# L4PER_PRM register map
Vendor: Texas Instruments
Peripheral module from a debugger description file (folder omap4460).
Registers are 32-bit, access not given, reset 0x1 unless marked. A register's access mark holds for its fields unless they carry their own. Offsets are as the file gives them; lines under a group give offsets from that group; [hi:lo] are bit positions; {n}, {i} and the like mark numbered series; 'fields as' and 'values as' point back to an identical list; <NAME> marks a mode.

## L4PER_PRM
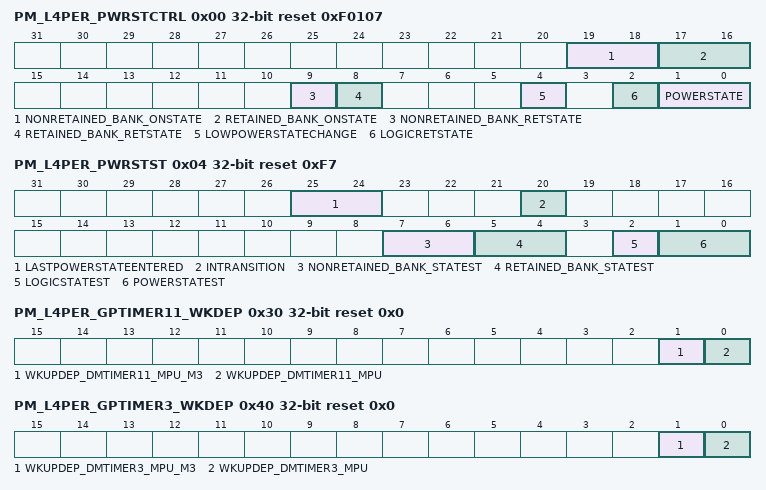
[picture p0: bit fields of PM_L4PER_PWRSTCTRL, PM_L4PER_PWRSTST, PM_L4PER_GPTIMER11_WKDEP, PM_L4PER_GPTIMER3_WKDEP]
0x00 PM_L4PER_PWRSTCTRL reset 0xF0107 — This register controls the L4PER power state to reach upon a domain sleep transition
  [19:18] NONRETAINED_BANK_ONSTATE — NONRETAINED_BANK state when domain is ON. (access R Rreturns1s)
    3=NONRETAINED_BANK_ONSTATE_3_r (Memory bank is on when the domain is ON.)
  [17:16] RETAINED_BANK_ONSTATE — RETAINED_BANK state when domain is ON. (access R Rreturns1s)
    3=RETAINED_BANK_ONSTATE_3_r (Memory bank is on when the domain is ON.)
  [9] NONRETAINED_BANK_RETSTATE ro — NONRETAINED_BANK state when domain is RETENTION.
    0=NONRETAINED_BANK_RETSTATE_0_r (Memory bank is off when the domain is in the RETENTION state.)
  [8] RETAINED_BANK_RETSTATE — RETAINED_BANK state when domain is RETENTION. (access R Rreturns1s)
    1=RETAINED_BANK_RETSTATE_1_r (Memory bank is retained when domain is in RETENTION state.)
  [4] LOWPOWERSTATECHANGE — Power state change request when domain has already performed a sleep transition. Allows going into deeper low power state without waking up the power domain. (access RW WSpecial)
    0=Do not request a low power state change; 1=Request a low power state change. This bit is automatically cleared when the power state is effectively changed or when power state is ON.
  [2] LOGICRETSTATE rw — Logic state when power domain is RETENTION
    0=Only retention registers are retained and remaing logic is off when the domain is in RETENTION state; 1=Whole logic is retained when domain is in RETENTION state
  [1:0] POWERSTATE rw — Power state control
    1=RETENTION state; 2=INACTIVE state; 3=ON State
0x04 PM_L4PER_PWRSTST reset 0xF7 — This register provides a status on the current L4PER power domain state. [warm reset insensitive]
  [25:24] LASTPOWERSTATEENTERED — Last low power state entered. Set to 0x3 upon write of the same only. This register is intended for debug purpose only. (access RW W1toSet)
    3=LASTPOWERSTATEENTERED_3_r (Power domain was previously ON-ACTIVE); 2=LASTPOWERSTATEENTERED_2_r (Power domain was previously ON-INACTIVE); 1=LASTPOWERSTATEENTERED_1_r (Power domain was previously in RETENTION); 0=LASTPOWERSTATEENTERED_0_r (Power domain was previously OFF)
  [20] INTRANSITION ro — Domain transition status
    0=INTRANSITION_0_r (No ongoing transition on power domain); 1=INTRANSITION_1_r (Power domain transition is in progress.)
  [7:6] NONRETAINED_BANK_STATEST ro — NONRETAINED_BANK state status
    0=NONRETAINED_BANK_STATEST_0_r (Memory is OFF); 1=NONRETAINED_BANK_STATEST_1_r (Reserved); 2=NONRETAINED_BANK_STATEST_2_r (Reserved); 3=NONRETAINED_BANK_STATEST_3_r (Memory is ON)
  [5:4] RETAINED_BANK_STATEST ro — RETAINED_BANK state status
    0=RETAINED_BANK_STATEST_0_r (Memory is OFF); 1=RETAINED_BANK_STATEST_1_r (Memory is RETENTION); 2=RETAINED_BANK_STATEST_2_r (Reserved); 3=RETAINED_BANK_STATEST_3_r (Memory is ON)
  [2] LOGICSTATEST ro — Logic state status
    0=LOGICSTATEST_0_r (Logic in domain is OFF); 1=LOGICSTATEST_1_r (Logic in domain is ON)
  [1:0] POWERSTATEST ro — Current power state status
    0=POWERSTATEST_0_r (Reserved); 1=POWERSTATEST_1_r (Power domain is in RETENTION); 2=POWERSTATEST_2_r (Power domain is ON-INACTIVE); 3=POWERSTATEST_3_r (Power domain is ON-ACTIVE)
0x28 PM_L4PER_GPTIMER10_WKDEP — This register controls wakeup dependency based on DMTIMER10 service requests.
  [0] WKUPDEP_DMTIMER10_MPU — Wakeup dependency from DMTIMER10 module (softwareakeup signal) towards MPU + L3_1 + L3_2 domains (access R Rreturns1s)
    1=WKUPDEP_DMTIMER10_MPU_1_r (Dependency is enabled)
0x2C RM_L4PER_GPTIMER10_CONTEXT — This register contains dedicated DMTIMER10 context statuses. [warm reset insensitive]
  [0] LOSTCONTEXT_DFF — Specify if DFF-based context has been lost due to a previous power transition or other reset source. (set upon assertion of L4_PER_RST signal) (access RW W1toClr)
    0=Context has been maintained; 1=Context has been lost
0x30 PM_L4PER_GPTIMER11_WKDEP access per field reset 0x0 — This register controls wakeup dependency based on DMTIMER11 service requests.
  [1] WKUPDEP_DMTIMER11_MPU_M3 rw — Wakeup dependency from DMTIMER11 module (softwareakeup signal) towards MPU_A3 + L3_2 domains
    0=Dependency is disabled; 1=Dependency is enabled
  [0] WKUPDEP_DMTIMER11_MPU rw — Wakeup dependency from DMTIMER11 module (softwareakeup signal) towards MPU + L3_1 + L3_2 domains
    0=Dependency is disabled; 1=Dependency is enabled
0x34 RM_L4PER_GPTIMER11_CONTEXT — This register contains dedicated DMTIMER11 context statuses. [warm reset insensitive]
  fields as RM_L4PER_GPTIMER10_CONTEXT
0x38 PM_L4PER_GPTIMER2_WKDEP — This register controls wakeup dependency based on DMTIMER2 service requests.
  [0] WKUPDEP_DMTIMER2_MPU — Wakeup dependency from DMTIMER2 module (softwareakeup signal) towards MPU + L3_1 + L3_2 domains (access R Rreturns1s)
    1=WKUPDEP_DMTIMER2_MPU_1_r (Dependency is enabled)
{0x2C+8i} RM_L4PER_GPTIMER{i}_CONTEXT (i=2..4) — This register contains dedicated DMTIMER{i} context statuses. [warm reset insensitive]
  fields as RM_L4PER_GPTIMER10_CONTEXT
0x40 PM_L4PER_GPTIMER3_WKDEP access per field reset 0x0 — This register controls wakeup dependency based on DMTIMER3 service requests.
  [1] WKUPDEP_DMTIMER3_MPU_M3 rw — Wakeup dependency from DMTIMER3 module (softwareakeup signal) towards MPU_A3 + L3_2 domains
    0=Dependency is disabled; 1=Dependency is enabled
  [0] WKUPDEP_DMTIMER3_MPU rw — Wakeup dependency from DMTIMER3 module (softwareakeup signal) towards MPU + L3_1 + L3_2 domains
    0=Dependency is disabled; 1=Dependency is enabled
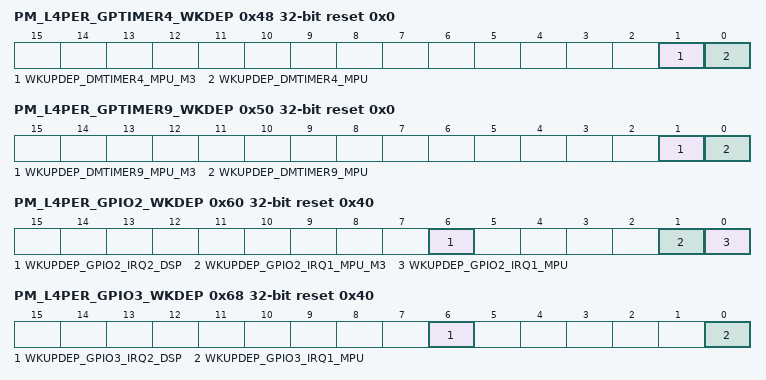
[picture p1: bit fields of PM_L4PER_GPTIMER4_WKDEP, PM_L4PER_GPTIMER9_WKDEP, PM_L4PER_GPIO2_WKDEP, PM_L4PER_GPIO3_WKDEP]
0x48 PM_L4PER_GPTIMER4_WKDEP access per field reset 0x0 — This register controls wakeup dependency based on DMTIMER4 service requests.
  [1] WKUPDEP_DMTIMER4_MPU_M3 rw — Wakeup dependency from DMTIMER4 module (softwareakeup signal) towards MPU_A3 + L3_2 domains
    0=Dependency is disabled; 1=Dependency is enabled
  [0] WKUPDEP_DMTIMER4_MPU rw — Wakeup dependency from DMTIMER4 module (softwareakeup signal) towards MPU + L3_1 + L3_2 domains
    0=Dependency is disabled; 1=Dependency is enabled
0x50 PM_L4PER_GPTIMER9_WKDEP access per field reset 0x0 — This register controls wakeup dependency based on DMTIMER9 service requests.
  [1] WKUPDEP_DMTIMER9_MPU_M3 rw — Wakeup dependency from DMTIMER9 module (softwareakeup signal) towards MPU_A3 + L3_2 domains
    0=Dependency is disabled; 1=Dependency is enabled
  [0] WKUPDEP_DMTIMER9_MPU rw — Wakeup dependency from DMTIMER9 module (softwareakeup signal) towards MPU + L3_1 + L3_2 domains
    0=Dependency is disabled; 1=Dependency is enabled
0x54 RM_L4PER_GPTIMER9_CONTEXT — This register contains dedicated DMTIMER9 context statuses. [warm reset insensitive]
  fields as RM_L4PER_GPTIMER10_CONTEXT
0x5C RM_L4PER_ELM_CONTEXT — This register contains dedicated ELM context statuses. [warm reset insensitive]
  fields as RM_L4PER_GPTIMER10_CONTEXT
0x60 PM_L4PER_GPIO2_WKDEP reset 0x40 — This register controls wakeup dependency based on GPIO2 service requests.
  [6] WKUPDEP_GPIO2_IRQ2_DSP — Wakeup dependency from GPIO2 module (POINTRsoftwareAKEUP2 signal) towards DSP + L3_1 + L3_2 domains (access R Rreturns1s)
    1=WKUPDEP_GPIO2_IRQ2_DSP_1_r (Dependency is enabled)
  [1] WKUPDEP_GPIO2_IRQ1_MPU_M3 rw — Wakeup dependency from GPIO2 module (POINTRsoftwareAKEUP1 signal) module towards MPU_A3 + L3_2 domains
    0=Dependency is disabled; 1=Dependency is enabled
  [0] WKUPDEP_GPIO2_IRQ1_MPU rw — Wakeup dependency from GPIO2 module (POINTRsoftwareAKEUP1 signal) towards MPU + L3_1 + L3_2 domains
    0=Dependency is disabled; 1=Dependency is enabled
{0x54+8i} RM_L4PER_GPIO{i}_CONTEXT reset 0x2 (i=2..6) — This register contains dedicated GPIO{i} context statuses. [warm reset insensitive]
  [1] LOSTCONTEXT_RFF — Specify if RFF-based context has been lost due to a previous power transition or other reset source. (set upon assertion of L4_PER_RET_RST signal) (access RW W1toClr)
    0=Context has been maintained; 1=Context has been lost
0x68 PM_L4PER_GPIO3_WKDEP reset 0x40 — This register controls wakeup dependency based on GPIO3 service requests.
  [6] WKUPDEP_GPIO3_IRQ2_DSP — Wakeup dependency from GPIO3 module (POINTRsoftwareAKEUP2 signal) towards DSP + L3_1 + L3_2 domains (access R Rreturns1s)
    1=WKUPDEP_GPIO3_IRQ2_DSP_1_r (Dependency is enabled)
  [0] WKUPDEP_GPIO3_IRQ1_MPU rw — Wakeup dependency from GPIO3 module (POINTRsoftwareAKEUP1 signal) towards MPU + L3_1 + L3_2 domains
    0=Dependency is disabled; 1=Dependency is enabled
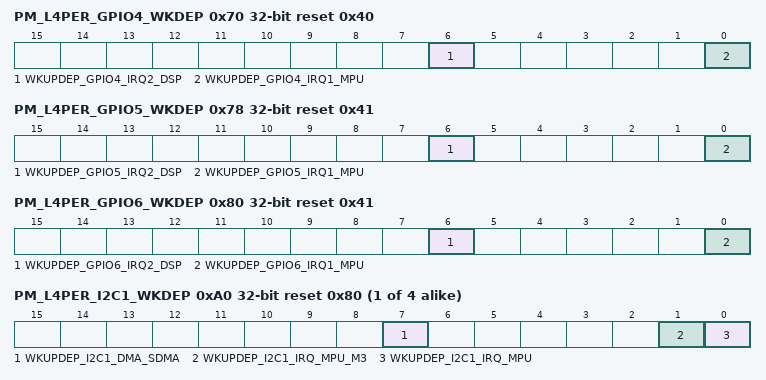
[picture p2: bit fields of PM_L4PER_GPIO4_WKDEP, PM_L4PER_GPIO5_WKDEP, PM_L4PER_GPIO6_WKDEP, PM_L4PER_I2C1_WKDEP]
0x70 PM_L4PER_GPIO4_WKDEP reset 0x40 — This register controls wakeup dependency based on GPIO4 service requests.
  [6] WKUPDEP_GPIO4_IRQ2_DSP — Wakeup dependency from GPIO4 module (POINTRsoftwareAKEUP2 signal) towards DSP + L3_1 + L3_2 domains (access R Rreturns1s)
    1=WKUPDEP_GPIO4_IRQ2_DSP_1_r (Dependency is enabled)
  [0] WKUPDEP_GPIO4_IRQ1_MPU rw — Wakeup dependency from GPIO4 module (POINTRsoftwareAKEUP1 signal) towards MPU + L3_1 + L3_2 domains
    0=Dependency is disabled; 1=Dependency is enabled
0x78 PM_L4PER_GPIO5_WKDEP reset 0x41 — This register controls wakeup dependency based on GPIO5 service requests.
  [6] WKUPDEP_GPIO5_IRQ2_DSP — Wakeup dependency from GPIO5 module (POINTRsoftwareAKEUP2 signal) towards DSP + L3_1 + L3_2 domains (access R Rreturns1s)
    1=WKUPDEP_GPIO5_IRQ2_DSP_1_r (Dependency is enabled)
  [0] WKUPDEP_GPIO5_IRQ1_MPU — Wakeup dependency from GPIO5 module (POINTRsoftwareAKEUP1 signal) towards MPU + L3_1 + L3_2 domains (access R Rreturns1s)
    1=WKUPDEP_GPIO5_IRQ1_MPU_1_r (Dependency is enabled)
0x80 PM_L4PER_GPIO6_WKDEP reset 0x41 — This register controls wakeup dependency based on GPIO6 service requests.
  [6] WKUPDEP_GPIO6_IRQ2_DSP — Wakeup dependency from GPIO6 module (POINTRsoftwareAKEUP2 signal) towards DSP + L3_1 + L3_2 domains (access R Rreturns1s)
    1=WKUPDEP_GPIO6_IRQ2_DSP_1_r (Dependency is enabled)
  [0] WKUPDEP_GPIO6_IRQ1_MPU — Wakeup dependency from GPIO6 module (POINTRsoftwareAKEUP1 signal) towards MPU + L3_1 + L3_2 domains (access R Rreturns1s)
    1=WKUPDEP_GPIO6_IRQ1_MPU_1_r (Dependency is enabled)
0x8C RM_L4PER_HDQ1W_CONTEXT — This register contains dedicated HDQ1W context statuses. [warm reset insensitive]
  fields as RM_L4PER_GPTIMER10_CONTEXT
{0x98+8i} PM_L4PER_I2C{i}_WKDEP reset 0x80 (i=1..4) — This register controls wakeup dependency based on I2C{i} service requests.
  [7] WKUPDEP_I2C{i}_DMA_SDMA — Wakeup dependency from I2C{i} module (softwareakeup_dma signal) towards SDMA + L3_2 domains (access R Rreturns1s)
    1=WKUPDEP_I2C{i}_DMA_SDMA_1_r (Dependency is enabled)
  [1] WKUPDEP_I2C{i}_IRQ_MPU_M3 rw — Wakeup dependency from I2C{i} module (softwareakeup_irq signal) towards MPU_A3 + L3_2 domains
    0=Dependency is disabled; 1=Dependency is enabled
  [0] WKUPDEP_I2C{i}_IRQ_MPU rw — Wakeup dependency from I2C{i} module (softwareakeup_irq signal) towards MPU + L3_1 + L3_2 domains
    0=Dependency is disabled; 1=Dependency is enabled
0xA4 RM_L4PER_I2C1_CONTEXT reset 0x2 — This register contains dedicated I2C1 context statuses. [warm reset insensitive]
  fields as RM_L4PER_GPIO2_CONTEXT
{0x9C+8i} RM_L4PER_I2C{i}_CONTEXT (i=2..4) — This register contains dedicated I2C{i} context statuses. [warm reset insensitive]
  fields as RM_L4PER_GPTIMER10_CONTEXT
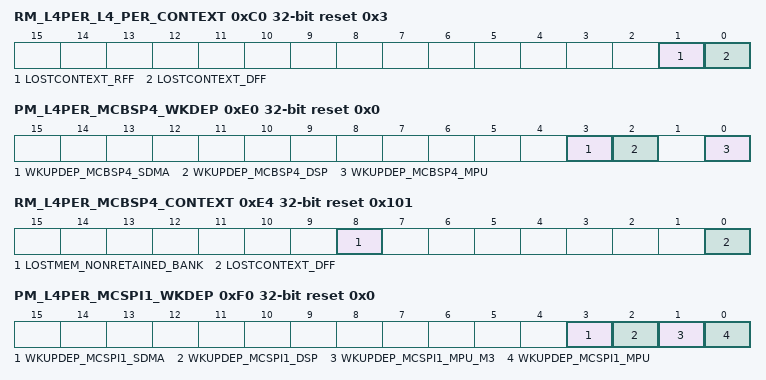
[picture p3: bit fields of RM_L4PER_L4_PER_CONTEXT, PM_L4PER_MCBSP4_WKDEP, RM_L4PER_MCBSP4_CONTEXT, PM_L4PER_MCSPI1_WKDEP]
0xC0 RM_L4PER_L4_PER_CONTEXT reset 0x3 — This register contains dedicated L4_PER context statuses. [warm reset insensitive]
  [1] LOSTCONTEXT_RFF — Specify if RFF-based context has been lost due to a previous power transition or other reset source. (set upon assertion of L4_PER_PWRON_RET_RST signal) (access RW W1toClr)
    0=Context has been maintained; 1=Context has been lost
  [0] LOSTCONTEXT_DFF — Specify if DFF-based context has been lost due to a previous power transition or other reset source. (set upon assertion of L4_PER_RST signal) (access RW W1toClr)
    0=Context has been maintained; 1=Context has been lost
0xE0 PM_L4PER_MCBSP4_WKDEP access per field reset 0x0 — This register controls wakeup dependency based on MCBSP4 service requests.
  [all] fields
    0=Dependency is disabled; 1=Dependency is enabled
  [3] WKUPDEP_MCBSP4_SDMA rw — Wakeup dependency from MCBSP4 module (softwareakeup signal) towards SDMA + L3_2 domains
  [2] WKUPDEP_MCBSP4_DSP rw — Wakeup dependency from MCBSP4 module (softwareakeup signal) towards DSP + L3_1 + L3_2 domain
  [0] WKUPDEP_MCBSP4_MPU rw — Wakeup dependency from MCBSP4 module (softwareakeup signal) towards MPU + L3_1 + L3_2 domain
0xE4 RM_L4PER_MCBSP4_CONTEXT reset 0x101 — This register contains dedicated MCBSP4 context statuses. [warm reset insensitive]
  [8] LOSTMEM_NONRETAINED_BANK — Specify if memory-based context in NONRETAINED_BANK memory bank has been lost due to a previous power transition or other reset source. (access RW W1toClr)
    0=Context has been maintained; 1=Context has been lost
  [0] LOSTCONTEXT_DFF — Specify if DFF-based context has been lost due to a previous power transition or other reset source. (set upon assertion of L4_PER_RST signal) (access RW W1toClr)
    0=Context has been maintained; 1=Context has been lost
0xF0 PM_L4PER_MCSPI1_WKDEP access per field reset 0x0 — This register controls wakeup dependency based on MCSPI1 service requests.
  [all] fields
    0=Dependency is disabled; 1=Dependency is enabled
  [3] WKUPDEP_MCSPI1_SDMA rw — Wakeup dependency from MCSPI1 module (softwareakeup signal) towards SDMA + L3_2 domains
  [2] WKUPDEP_MCSPI1_DSP rw — Wakeup dependency from MCSPI1 module (softwareakeup signal) towards DSP + L3_1 + L3_2 domains
  [1] WKUPDEP_MCSPI1_MPU_M3 rw — Wakeup dependency from MCSPI1 module (softwareakeup signal) towards MPU_A3 + L3_2 domains
  [0] WKUPDEP_MCSPI1_MPU rw — Wakeup dependency from MCSPI1 module (softwareakeup signal) towards MPU + L3_1 + L3_2 domains
{0xEC+8i} RM_L4PER_MCSPI{i}_CONTEXT (i=1..4) — This register contains dedicated MCSPI{i} context statuses. [warm reset insensitive]
  fields as RM_L4PER_GPTIMER10_CONTEXT
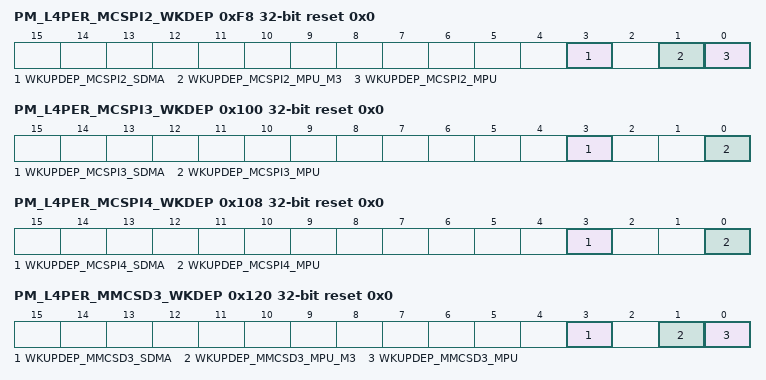
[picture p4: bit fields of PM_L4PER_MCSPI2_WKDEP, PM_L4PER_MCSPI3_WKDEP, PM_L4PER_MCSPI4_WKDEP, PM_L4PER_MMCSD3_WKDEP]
0xF8 PM_L4PER_MCSPI2_WKDEP access per field reset 0x0 — This register controls wakeup dependency based on MCSPI2 service requests.
  [all] fields
    0=Dependency is disabled; 1=Dependency is enabled
  [3] WKUPDEP_MCSPI2_SDMA rw — Wakeup dependency from MCSPI2 module (softwareakeup signal) towards SDMA + L3_2 domains
  [1] WKUPDEP_MCSPI2_MPU_M3 rw — Wakeup dependency from MCSPI2 module (softwareakeup signal) towards MPU_A3 + L3_2 domains
  [0] WKUPDEP_MCSPI2_MPU rw — Wakeup dependency from MCSPI2 module (softwareakeup signal) towards MPU + L3_1 + L3_2 domains
0x100 PM_L4PER_MCSPI3_WKDEP access per field reset 0x0 — This register controls wakeup dependency based on MCSPI3 service requests.
  [3] WKUPDEP_MCSPI3_SDMA rw — Wakeup dependency from MCSPI3 module (softwareakeup signal) towards SDMA + L3_2 domains
    0=Dependency is disabled; 1=Dependency is enabled
  [0] WKUPDEP_MCSPI3_MPU rw — Wakeup dependency from MCSPI3 module (softwareakeup signal) towards MPU + L3_1 + L3_2 domains
    0=Dependency is disabled; 1=Dependency is enabled
0x108 PM_L4PER_MCSPI4_WKDEP access per field reset 0x0 — This register controls wakeup dependency based on MCSPI4 service requests.
  [3] WKUPDEP_MCSPI4_SDMA rw — Wakeup dependency from MCSPI4 module (softwareakeup signal) towards SDMA + L3_2 domains
    0=Dependency is disabled; 1=Dependency is enabled
  [0] WKUPDEP_MCSPI4_MPU rw — Wakeup dependency from MCSPI4 module (softwareakeup signal) towards MPU + L3_1 + L3_2 domains
    0=Dependency is disabled; 1=Dependency is enabled
0x120 PM_L4PER_MMCSD3_WKDEP access per field reset 0x0 — This register controls wakeup dependency based on MMCSD3 service requests.
  [all] fields
    0=Dependency is disabled; 1=Dependency is enabled
  [3] WKUPDEP_MMCSD3_SDMA rw — Wakeup dependency from MMCSD3 module (softwareakeup signal) towards SDMA + L3_2 domains
  [1] WKUPDEP_MMCSD3_MPU_M3 rw — Wakeup dependency from MMCSD3 module (softwareakeup signal) towards MPU_A3 + L3_2 domains
  [0] WKUPDEP_MMCSD3_MPU rw — Wakeup dependency from MMCSD3 module (softwareakeup signal) towards MPU + L3_1 + L3_2 domains
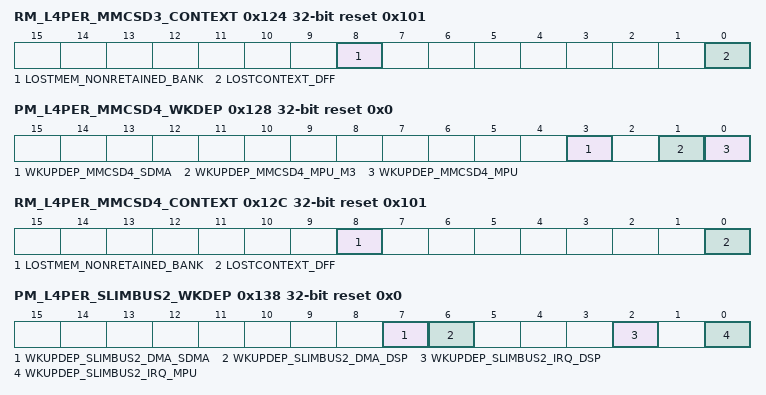
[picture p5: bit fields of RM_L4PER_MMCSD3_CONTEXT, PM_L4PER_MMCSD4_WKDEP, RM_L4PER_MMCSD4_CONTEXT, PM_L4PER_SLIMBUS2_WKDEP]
0x124 RM_L4PER_MMCSD3_CONTEXT reset 0x101 — This register contains dedicated MMCSD3 context statuses. [warm reset insensitive]
  fields as RM_L4PER_MCBSP4_CONTEXT
0x128 PM_L4PER_MMCSD4_WKDEP access per field reset 0x0 — This register controls wakeup dependency based on MMCSD4 service requests.
  [all] fields
    0=Dependency is disabled; 1=Dependency is enabled
  [3] WKUPDEP_MMCSD4_SDMA rw — Wakeup dependency from MMCSD4 module (softwareakeup signal) towards SDMA + L3_2 domains
  [1] WKUPDEP_MMCSD4_MPU_M3 rw — Wakeup dependency from MMCSD4 module (softwareakeup signal) towards MPU_A3 + L3_2 domains
  [0] WKUPDEP_MMCSD4_MPU rw — Wakeup dependency from MMCSD4 module (softwareakeup signal) towards MPU + L3_1 + L3_2 domains
0x12C RM_L4PER_MMCSD4_CONTEXT reset 0x101 — This register contains dedicated MMCSD4 context statuses. [warm reset insensitive]
  fields as RM_L4PER_MCBSP4_CONTEXT
0x138 PM_L4PER_SLIMBUS2_WKDEP access per field reset 0x0 — This register controls wakeup dependency based on SLIMBUS2 service requests.
  [all] fields
    0=Dependency is disabled; 1=Dependency is enabled
  [7] WKUPDEP_SLIMBUS2_DMA_SDMA rw — Wakeup dependency from SLIMBUS2 module (softwareakeup_dma signal) towards SDMA + L3_2 domains
  [6] WKUPDEP_SLIMBUS2_DMA_DSP rw — Wakeup dependency from SLIMBUS2 module (softwareakeup_dma signal) towards DSP + L3_1 + L3_2 domains
  [2] WKUPDEP_SLIMBUS2_IRQ_DSP rw — Wakeup dependency from SLIMBUS2 module (softwareakeup_irq signal) towards DSP + L3_1 + L3_2 domains
  [0] WKUPDEP_SLIMBUS2_IRQ_MPU rw — Wakeup dependency from SLIMBUS2 module (softwareakeup_irq signal) towards MPU + L3_1 + L3_2 domains
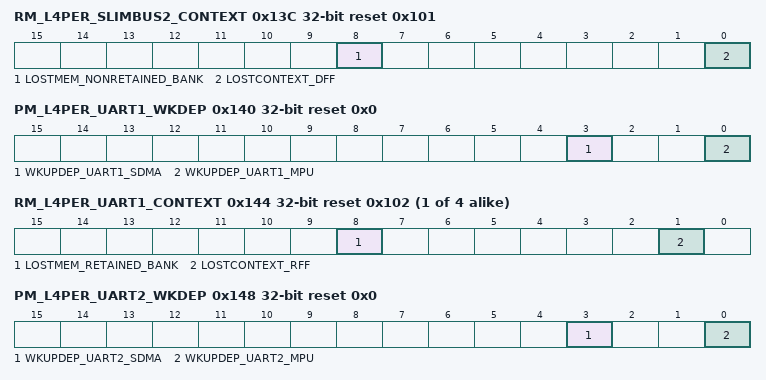
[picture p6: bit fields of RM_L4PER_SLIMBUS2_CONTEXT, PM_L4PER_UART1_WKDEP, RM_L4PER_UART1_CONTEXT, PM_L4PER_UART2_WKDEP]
0x13C RM_L4PER_SLIMBUS2_CONTEXT reset 0x101 — This register contains dedicated SLIMBUS2 context statuses. [warm reset insensitive]
  fields as RM_L4PER_MCBSP4_CONTEXT
0x140 PM_L4PER_UART1_WKDEP access per field reset 0x0 — This register controls wakeup dependency based on UART1 service requests.
  [3] WKUPDEP_UART1_SDMA rw — Wakeup dependency from UART1 module (softwareakeup signal) towards SDMA + L3_2 domains
    0=Dependency is disabled; 1=Dependency is enabled
  [0] WKUPDEP_UART1_MPU rw — Wakeup dependency from UART1 module (softwareakeup signal) towards MPU + L3_1 + L3_2 domains
    0=Dependency is disabled; 1=Dependency is enabled
{0x13C+8i} RM_L4PER_UART{i}_CONTEXT reset 0x102 (i=1..4) — This register contains dedicated UART{i} context statuses. [warm reset insensitive]
  [8] LOSTMEM_RETAINED_BANK — Specify if memory-based context in RETAINED_BANK memory bank has been lost due to a previous power transition or other reset source. (access RW W1toClr)
    0=Context has been maintained; 1=Context has been lost
  [1] LOSTCONTEXT_RFF — Specify if RFF-based context has been lost due to a previous power transition or other reset source. (set upon assertion of L4_PER_RET_RST signal) (access RW W1toClr)
    0=Context has been maintained; 1=Context has been lost
0x148 PM_L4PER_UART2_WKDEP access per field reset 0x0 — This register controls wakeup dependency based on UART2 service requests.
  [3] WKUPDEP_UART2_SDMA rw — Wakeup dependency from UART2 module (softwareakeup signal) towards SDMA + L3_2 domains
    0=Dependency is disabled; 1=Dependency is enabled
  [0] WKUPDEP_UART2_MPU rw — Wakeup dependency from UART2 module (softwareakeup signal) towards MPU + L3_1 + L3_2 domains
    0=Dependency is disabled; 1=Dependency is enabled
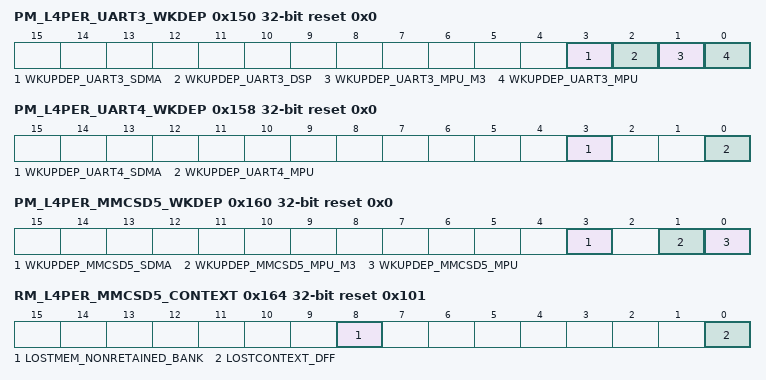
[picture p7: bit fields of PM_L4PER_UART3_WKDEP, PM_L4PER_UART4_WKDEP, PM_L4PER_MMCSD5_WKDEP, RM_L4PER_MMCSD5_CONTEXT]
0x150 PM_L4PER_UART3_WKDEP access per field reset 0x0 — This register controls wakeup dependency based on UART3 service requests.
  [all] fields
    0=Dependency is disabled; 1=Dependency is enabled
  [3] WKUPDEP_UART3_SDMA rw — Wakeup dependency from UART3 module (softwareakeup signal) towards SDMA + L3_2 domains
  [2] WKUPDEP_UART3_DSP rw — Wakeup dependency from UART3 module (softwareakeup signal) towards DSP + L3_1 + L3_2 domains
  [1] WKUPDEP_UART3_MPU_M3 rw — Wakeup dependency from UART3 module (softwareakeup signal) towards MPU_A3 + L3_2 domains
  [0] WKUPDEP_UART3_MPU rw — Wakeup dependency from UART3 module (softwareakeup signal) towards MPU + L3_1 + L3_2 domains
0x158 PM_L4PER_UART4_WKDEP access per field reset 0x0 — This register controls wakeup dependency based on UART4 service requests.
  [3] WKUPDEP_UART4_SDMA rw — Wakeup dependency from UART4 module (softwareakeup signal) towards SDMA + L3_2 domains
    0=Dependency is disabled; 1=Dependency is enabled
  [0] WKUPDEP_UART4_MPU rw — Wakeup dependency from UART4 module (softwareakeup signal) towards MPU + L3_1 + L3_2 domains
    0=Dependency is disabled; 1=Dependency is enabled
0x160 PM_L4PER_MMCSD5_WKDEP access per field reset 0x0 — This register controls wakeup dependency based on MMCSD5 service requests.
  [all] fields
    0=Dependency is disabled; 1=Dependency is enabled
  [3] WKUPDEP_MMCSD5_SDMA rw — Wakeup dependency from MMCSD5 module (softwareakeup signal) towards SDMA + L3_2 domains
  [1] WKUPDEP_MMCSD5_MPU_M3 rw — Wakeup dependency from MMCSD5 module (softwareakeup signal) towards MPU_A3 + L3_2 domains
  [0] WKUPDEP_MMCSD5_MPU rw — Wakeup dependency from MMCSD5 module (softwareakeup signal) towards MPU + L3_1 + L3_2 domains
0x164 RM_L4PER_MMCSD5_CONTEXT reset 0x101 — This register contains dedicated MMCSD5 context statuses. [warm reset insensitive]
  fields as RM_L4PER_MCBSP4_CONTEXT
0x1A4 RM_L4SEC_AES1_CONTEXT reset 0x2 — This register contains dedicated AES1 context statuses. [warm reset insensitive]
  fields as RM_L4PER_GPIO2_CONTEXT
0x1AC RM_L4SEC_AES2_CONTEXT reset 0x2 — This register contains dedicated AES2 context statuses. [warm reset insensitive]
  fields as RM_L4PER_GPIO2_CONTEXT
0x1B4 RM_L4SEC_DES3DES_CONTEXT reset 0x2 — This register contains dedicated DES3DES context statuses. [warm reset insensitive]
  fields as RM_L4PER_GPIO2_CONTEXT
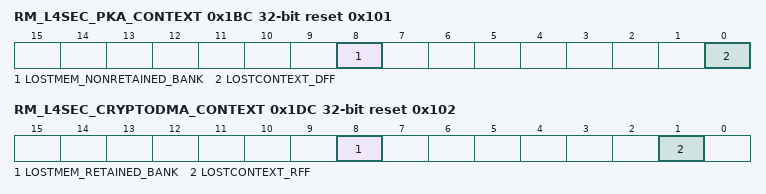
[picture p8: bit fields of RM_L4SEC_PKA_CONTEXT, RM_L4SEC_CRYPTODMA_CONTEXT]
0x1BC RM_L4SEC_PKA_CONTEXT reset 0x101 — This register contains dedicated PKA context statuses. [warm reset insensitive]
  [8] LOSTMEM_NONRETAINED_BANK — Specify if memory-based context in NONRETAINED_BANK memory bank has been lost due to a previous power transition or other reset source. (access RW W1toClr)
    0=Context has been maintained; 1=Context has been lost
  [0] LOSTCONTEXT_DFF — Specify if DFF-based context has been lost due to a previous power transition or other reset source (set upon assertion of L4_PER_RST signal). (access RW W1toClr)
    0=Context has been maintained; 1=Context has been lost
0x1C4 RM_L4SEC_RNG_CONTEXT reset 0x2 — This register contains dedicated RNG context statuses. [warm reset insensitive]
  [1] LOSTCONTEXT_RFF — Specify if RFF-based context has been lost due to a previous power transition or other reset source (set upon assertion of L4_PER_RET_RST signal). (access RW W1toClr)
    0=Context has been maintained; 1=Context has been lost
0x1CC RM_L4SEC_SHA2MD5_CONTEXT reset 0x2 — This register contains dedicated SHA2MD5 context statuses. [warm reset insensitive]
  fields as RM_L4SEC_RNG_CONTEXT
0x1DC RM_L4SEC_CRYPTODMA_CONTEXT reset 0x102 — This register contains dedicated CRYPTODMA context statuses. [warm reset insensitive]
  [8] LOSTMEM_RETAINED_BANK — Specify if memory-based context in RETAINED_BANK memory bank has been lost due to a previous power transition or other reset source. (access RW W1toClr)
    0=Context has been maintained; 1=Context has been lost
  [1] LOSTCONTEXT_RFF — Specify if RFF-based context has been lost due to a previous power transition or other reset source (set upon assertion of L4_PER_RST signal). (access RW W1toClr)
    0=Context has been maintained; 1=Context has been lost
